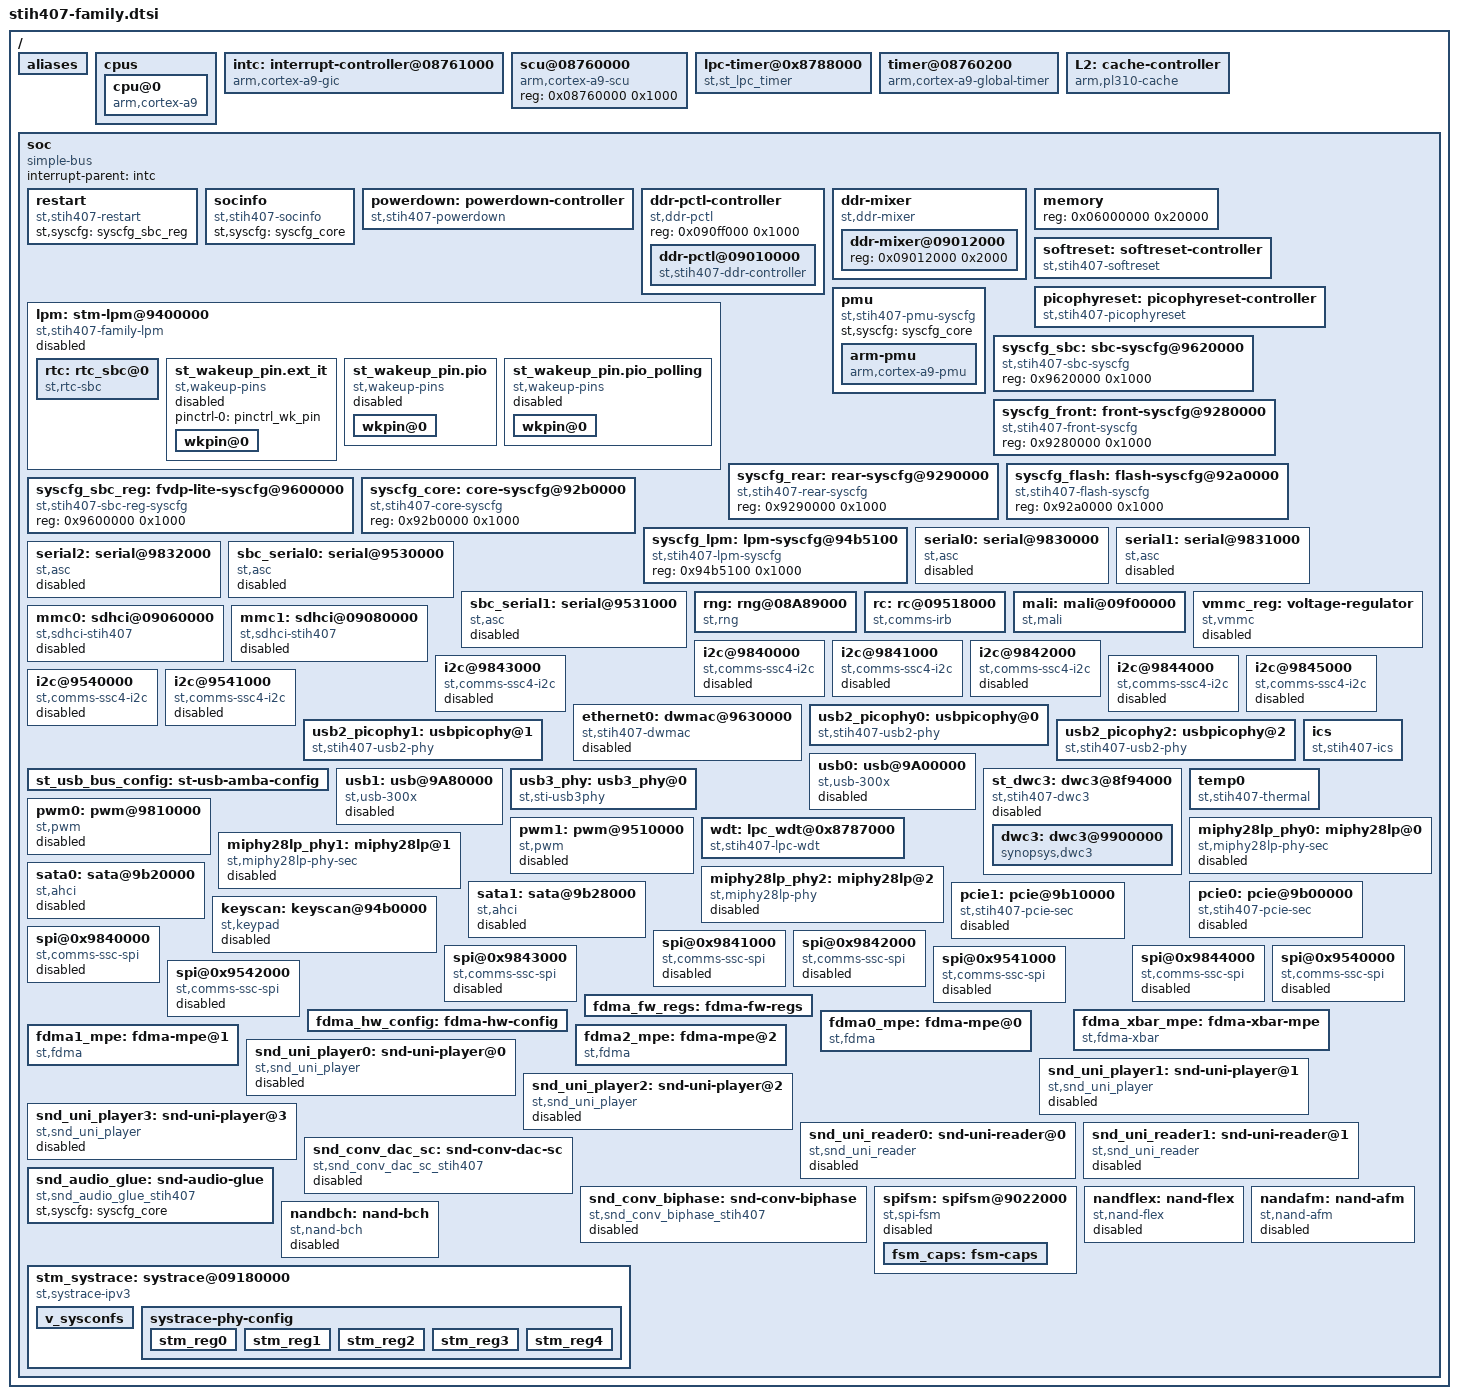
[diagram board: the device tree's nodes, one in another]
/*
 * Copyright (C) 2013 STMicroelectronics Limited.
 * Author: Giuseppe Cavallaro <peppe.cavallaro@st.com>
 *
 * This program is free software; you can redistribute it and/or modify
 * it under the terms of the GNU General Public License version 2 as
 * publishhed by the Free Software Foundation.
 */
#include "stih407-pinctrl.dtsi"
#include <dt-bindings/reset-controller/stih407-resets.h>
#include <dt-bindings/phy/phy-miphy28lp.h>
#include <dt-bindings/gpio/gpio-st-wakeup.h>

#define CLK_PCM_0 0
#define CLK_PCM_1 1
#define CLK_PCM_2 2
#define CLK_SPDIF 3

/ {
	#address-cells = <1>;
	#size-cells = <1>;

	aliases {
		fdma0 = &fdma0_mpe;
		fdma1 = &fdma1_mpe;
		fdma2 = &fdma2_mpe;
		fdmaxbar0 = &fdma_xbar_mpe;
	};

	cpus {
		#address-cells = <1>;
		#size-cells = <0>;
		cpu@0 {
			device_type = "cpu";
			compatible = "arm,cortex-a9";
			reg = <0>;
			clocks = <&CLK_M_A9>;
			clock-names = "cpu";
			operating-points = <
				/* kHz    ignored */
				 1200000  1000000
				  600000  1000000
				  300000  1000000
			>;
			clock-latency = <100000>;
		};
	};

	intc: interrupt-controller@08761000 {
		compatible = "arm,cortex-a9-gic";
		#interrupt-cells = <3>;
		interrupt-controller;
		reg = <0x08761000 0x1000>,
		      <0x08760100 0x100>;
	};

	scu@08760000 {
		compatible = "arm,cortex-a9-scu";
		reg = <0x08760000 0x1000>;
	};

	lpc-timer@0x8788000 {
		compatible = "st,st_lpc_timer";
		reg = <0x8788000 0x1000>;
		clock-names = "lpc_clk";
		clocks = <&CLK_S_D3_FLEXGEN CLK_LPC_1>;
	};

	timer@08760200 {
		interrupt-parent = <&intc>;
		compatible = "arm,cortex-a9-global-timer";
		reg = <0x08760200 0x100>;
		interrupts = <GIC_PPI 11 IRQ_TYPE_LEVEL_HIGH>;
		clocks = <&arm_periph_clk>;
	};

	L2: cache-controller {
		compatible = "arm,pl310-cache";
		reg = <0x08762000 0x1000>;
		arm,data-latency = <3 3 3>;
		arm,tag-latency = <2 2 2>;
		cache-unified;
		cache-level = <2>;
	};

	soc {
		#address-cells = <1>;
		#size-cells = <1>;
		interrupt-parent = <&intc>;
		ranges;
		compatible = "simple-bus";

		restart {
			compatible = "st,stih407-restart";
			st,syscfg = <&syscfg_sbc_reg>;
		};

		socinfo {
			compatible = "st,stih407-socinfo";
			st,syscfg = <&syscfg_core>;
		};

		powerdown: powerdown-controller {
			#reset-cells = <1>;
			compatible = "st,stih407-powerdown";
		};

		ddr-pctl-controller {
			#address-cells = <1>;
			#size-cells = <1>;
			ranges;
			compatible = "st,ddr-pctl", "simple-bus";
			reg = <0x090ff000 0x1000>;
			reg-names = "ddr_pll";
			ddr-pctl@09010000 {
				compatible = "st,stih407-ddr-controller", "st,ddr-controller";
				reg = <0x09010000 0x2000>;
				st,syscfg = <&syscfg_core>;
			};
		};

		ddr-mixer {
			#address-cells = <1>;
			#size-cells = <1>;
			ranges;
			compatible = "st,ddr-mixer", "simple-bus";
			ddr-mixer@09012000 {
				reg = <0x09012000 0x2000>;
			};
		};

		memory {
			device_type = "eram";
			reg = <0x06000000 0x20000>;
			reg-names = "eram_1";
		};

		lpm:stm-lpm@9400000 {
			compatible = "st,stih407-family-lpm", "st,lpm";
			reg = <0x9400000 0xa0000>,
			<0x94b4000 0x400>,
			<0x94b5100 0x100>,
			<0x020000 0x0>;
			reg-names = "base", "mailbox", "confreg", "pmem";
			interrupts = <GIC_SPI 144 IRQ_TYPE_NONE>;
			st,fw_name = "lpm-fw-STiH407.elf";
			status = "disabled";

			rtc: rtc_sbc@0 {
				compatible = "st,rtc-sbc";
			};

			st_wakeup_pin.ext_it {
				compatible = "st,wakeup-pins";
				status = "disabled";
				pinctrl-names = "default";
				pinctrl-0 = <&pinctrl_wk_pin>;
				wkpin@0 {
					interrupts = <GIC_SPI 184 IRQ_TYPE_NONE>;
					label = "ext_it_wakeup";
					st,pio_use = <EXT_IT_WAKEUP_MODE>;
					st,ext_it_num = <2>;
				};
			};

			st_wakeup_pin.pio {
				compatible = "st,wakeup-pins";
				status = "disabled";
				wkpin@0 {
					label = "pio_wakeup";
					gpios = <&PIO3 3>;
					st,pio_use = <PIO_WAKEUP_MODE>;
					st,pio_dir = <GPIO_AS_INPUT>;
					st,int_enabled;
				};
			};

			st_wakeup_pin.pio_polling {
				compatible = "st,wakeup-pins";
				status = "disabled";
				wkpin@0 {
					label = "pio_polling_wakeup";
					gpios = <&PIO3 3>;
					st,pio_use = <PIO_WAKEUP_MODE>;
					st,pio_dir = <GPIO_AS_INPUT>;
					st,pio_level = <GPIO_ACTIVE_LOW>;
				};
			};
		};

		softreset: softreset-controller {
			#reset-cells = <1>;
			compatible = "st,stih407-softreset";
		};

		picophyreset: picophyreset-controller {
			#reset-cells = <1>;
			compatible = "st,stih407-picophyreset";
		};

		pmu {
			compatible = "st,stih407-pmu-syscfg";
			st,syscfg = <&syscfg_core>;

			arm-pmu {
				interrupt-parent = <&intc>;
				compatible = "arm,cortex-a9-pmu";
				interrupts = <GIC_PPI 15 IRQ_TYPE_LEVEL_HIGH>;
			};
		};

		syscfg_sbc:sbc-syscfg@9620000{
			compatible = "st,stih407-sbc-syscfg", "syscon";
			reg = <0x9620000 0x1000>;
		};

		syscfg_front:front-syscfg@9280000{
			compatible = "st,stih407-front-syscfg", "syscon";
			reg = <0x9280000 0x1000>;
		};

		syscfg_rear:rear-syscfg@9290000{
			compatible = "st,stih407-rear-syscfg", "syscon";
			reg = <0x9290000 0x1000>;
		};

		syscfg_flash:flash-syscfg@92a0000{
			compatible = "st,stih407-flash-syscfg", "syscon";
			reg = <0x92a0000 0x1000>;
		};

		syscfg_sbc_reg:fvdp-lite-syscfg@9600000{
			compatible = "st,stih407-sbc-reg-syscfg", "syscon";
			reg = <0x9600000 0x1000>;
		};

		syscfg_core:core-syscfg@92b0000{
			compatible = "st,stih407-core-syscfg", "syscon";
			reg = <0x92b0000 0x1000>;
		};

		syscfg_lpm:lpm-syscfg@94b5100{
			compatible = "st,stih407-lpm-syscfg", "syscon";
			reg = <0x94b5100 0x1000>;
		};

		/* Comms block ASCs */
		serial0: serial@9830000{
			compatible = "st,asc";
			status = "disabled";
			reg = <0x9830000 0x2c>;
			interrupts = <GIC_SPI 122 IRQ_TYPE_NONE>;
			pinctrl-names = "default";
			pinctrl-0 = <&pinctrl_serial0>;
			clocks = <&CLK_S_C0_FLEXGEN CLK_EXT2F_A9>;
		};

		serial1: serial@9831000{
			compatible = "st,asc";
			status = "disabled";
			reg = <0x9831000 0x2c>;
			interrupts = <GIC_SPI 123 IRQ_TYPE_NONE>;
			pinctrl-names = "default";
			pinctrl-0 = <&pinctrl_serial1>;
			clocks = <&CLK_S_C0_FLEXGEN CLK_EXT2F_A9>;
		};

		serial2: serial@9832000{
			compatible = "st,asc";
			status = "disabled";
			reg = <0x9832000 0x2c>;
			interrupts = <GIC_SPI 124 IRQ_TYPE_NONE>;
			pinctrl-names = "default";
			pinctrl-0 = <&pinctrl_serial2>;
			clocks = <&CLK_S_C0_FLEXGEN CLK_EXT2F_A9>;
		};

		/* SBC_ASC0 - UART10 */
		sbc_serial0: serial@9530000 {
			compatible = "st,asc";
			status = "disabled";
			reg = <0x9530000 0x2c>;
			interrupts = <GIC_SPI 138 IRQ_TYPE_NONE>;
			pinctrl-names = "default";
			pinctrl-0 = <&pinctrl_sbc_serial0>;
			clocks = <&CLK_SYSIN>;
		};

		/* SBC_ASC1 - UART11 */
		sbc_serial1: serial@9531000 {
			compatible = "st,asc";
			status = "disabled";
			reg = <0x9531000 0x2c>;
			interrupts = <GIC_SPI 139 IRQ_TYPE_NONE>;
			pinctrl-names = "default";
			pinctrl-0 = <&pinctrl_sbc_serial1>;
			clocks = <&CLK_SYSIN>;
		};

		/* RNG */
		rng: rng@08A89000 {
			compatible = "st,rng";
			reg = <0x08A89000 0x1000>;
			clocks = <&CLK_SYSIN>;
		};

		rc: rc@09518000 {
			compatible = "st,comms-irb";
			reg = <0x09518000 0x234>;
			interrupts = <GIC_SPI 132 IRQ_TYPE_NONE>;
			rx-mode = "infrared";
			pinctrl-names = "default";
			pinctrl-0 = <&pinctrl_ir>;
			clocks = <&CLK_SYSIN>;
			resets = <&softreset STIH407_IRB_SOFTRESET>;
		};

		mali: mali@09f00000 {
			compatible = "st,mali";
			reg = <0x09f01000 0x200>,
			      <0x09f00000 0x100>,
			      <0x09f03000 0x100>,
			      <0x09f08000 0x1100>,
			      <0x09f04000 0x100>,
			      <0x09f0a000 0x1100>,
			      <0x09f05000 0x100>,
			      <0x09f0c000 0x1100>,
			      <0x09f06000 0x100>,
			      <0x09f0e000 0x1100>,
			      <0x09f07000 0x100>;

			reg-names = "Mali_L2",
				    "Mali_GP",
				    "Mali_GP_MMU",
				    "Mali_PP0",
				    "Mali_PP0_MMU",
				    "Mali_PP1",
				    "Mali_PP1_MMU",
				    "Mali_PP2",
				    "Mali_PP2_MMU",
				    "Mali_PP3",
				    "Mali_PP3_MMU";

			interrupts = <GIC_SPI 49 IRQ_TYPE_NONE>,
				     <GIC_SPI 50 IRQ_TYPE_NONE>,
				     <GIC_SPI 41 IRQ_TYPE_NONE>,
				     <GIC_SPI 45 IRQ_TYPE_NONE>,
				     <GIC_SPI 42 IRQ_TYPE_NONE>,
				     <GIC_SPI 46 IRQ_TYPE_NONE>,
				     <GIC_SPI 43 IRQ_TYPE_NONE>,
				     <GIC_SPI 47 IRQ_TYPE_NONE>,
				     <GIC_SPI 44 IRQ_TYPE_NONE>,
				     <GIC_SPI 48 IRQ_TYPE_NONE>;

			interrupt-names = "Mali_GP_IRQ",
					  "Mali_GP_MMU_IRQ",
					  "Mali_PP0_IRQ",
					  "Mali_PP0_MMU_IRQ",
					  "Mali_PP1_IRQ",
					  "Mali_PP1_MMU_IRQ",
					  "Mali_PP2_IRQ",
					  "Mali_PP2_MMU_IRQ",
					  "Mali_PP3_IRQ",
					  "Mali_PP3_MMU_IRQ";

			clock-names = "gpu-clk";
			clocks = <&CLK_S_C0_FLEXGEN CLK_ICN_GPU>;
		};

		/*
		 * The table below summarizes which uses the FlashSS Top
		 * registers. For example the vsense register is exclusively
		 * mapped by the voltage regulator, the subset of registers
		 * to manage the eMMC RX/TX delay are only used inside the
		 * SDHCI ST driver.
		 *
		 *----------------------------------------------------------
		 * Offset	   Register		Driver
		 *----------------------------------------------------------
		 *   0x0	FLASHSS_CONFIG		NAND
		 *   0x4	VSENSE_CONFIG		Voltage Regulator
		 *   0x8	eMMC_TX_CLK_DELAY	SDHCI-ST
		 *		 ...
		 */

		vmmc_reg: voltage-regulator {
			compatible = "st,vmmc";
			regulator-name = "vmmc0";
			/* Control register for the VSENSE Module */
			reg = <0x9061004 0x4>;
			status = "disabled";
		};

		mmc0: sdhci@09060000 {
			compatible = "st,sdhci-stih407", "st,sdhci";
			status = "disabled";
			reg = <0x09060000 0x7ff>, <0x9061008 0x20>;
			reg-names = "mmc", "top-mmc-delay";
			interrupts = <GIC_SPI 92 IRQ_TYPE_NONE>;
			interrupt-names = "mmcirq";
			pinctrl-names = "default";
			pinctrl-0 = <&pinctrl_mmc0>;
			clock-names = "mmc";
			clocks = <&CLK_S_C0_FLEXGEN CLK_MMC_0>;
			st,no-hispd-bit;
			vmmc-supply = <&vmmc_reg>;
		};

		mmc1: sdhci@09080000 {
			compatible = "st,sdhci-stih407", "st,sdhci";
			status = "disabled";
			reg = <0x09080000 0x7ff>;
			reg-names = "mmc";
			interrupts = <GIC_SPI 90 IRQ_TYPE_NONE>;
			interrupt-names = "mmcirq";
			pinctrl-names = "default";
			pinctrl-0 = <&pinctrl_sd1>;
			clock-names = "mmc";
			clocks = <&CLK_S_C0_FLEXGEN CLK_MMC_1>;
			resets = <&softreset STIH407_MMC1_SOFTRESET>;
		};

		i2c@9840000 {
			compatible = "st,comms-ssc4-i2c";
			status = "disabled";
			interrupts = <GIC_SPI 112 IRQ_TYPE_LEVEL_HIGH>;
			reg = <0x9840000 0x110>;
			#address-cells = <1>;
			#size-cells = <0>;
			clocks = <&CLK_S_C0_FLEXGEN CLK_EXT2F_A9>;
			clock-names = "ssc";
			clock-frequency = <400000>;
			pinctrl-names = "default";
			pinctrl-0 = <&pinctrl_i2c0_default>;
		};

		i2c@9841000 {
			compatible = "st,comms-ssc4-i2c";
			status = "disabled";
			reg = <0x9841000 0x110>;
			interrupts = <GIC_SPI 113 IRQ_TYPE_LEVEL_HIGH>;
			#address-cells = <1>;
			#size-cells = <0>;
			clocks = <&CLK_S_C0_FLEXGEN CLK_EXT2F_A9>;
			clock-names = "ssc";
			clock-frequency = <400000>;
			pinctrl-names = "default";
			pinctrl-0 = <&pinctrl_i2c1_default>;
		};

		i2c@9842000 {
			compatible = "st,comms-ssc4-i2c";
			status = "disabled";
			reg = <0x9842000 0x110>;
			interrupts = <GIC_SPI 114 IRQ_TYPE_LEVEL_HIGH>;
			#address-cells = <1>;
			#size-cells = <0>;
			clocks = <&CLK_S_C0_FLEXGEN CLK_EXT2F_A9>;
			clock-names = "ssc";
			clock-frequency = <400000>;
			pinctrl-names = "default";
			pinctrl-0 = <&pinctrl_i2c2_default>;
		};

		i2c@9843000 {
			compatible = "st,comms-ssc4-i2c";
			status = "disabled";
			reg = <0x9843000 0x110>;
			interrupts = <GIC_SPI 115 IRQ_TYPE_LEVEL_HIGH>;
			#address-cells = <1>;
			#size-cells = <0>;
			clocks = <&CLK_S_C0_FLEXGEN CLK_EXT2F_A9>;
			clock-names = "ssc";
			clock-frequency = <400000>;
			pinctrl-names = "default";
			pinctrl-0 = <&pinctrl_i2c3_default>;
		};

		i2c@9844000 {
			compatible = "st,comms-ssc4-i2c";
			status = "disabled";
			reg = <0x9844000 0x110>;
			interrupts = <GIC_SPI 116 IRQ_TYPE_LEVEL_HIGH>;
			#address-cells = <1>;
			#size-cells = <0>;
			clocks = <&CLK_S_C0_FLEXGEN CLK_EXT2F_A9>;
			clock-names = "ssc";
			clock-frequency = <400000>;
			pinctrl-names = "default";
			pinctrl-0 = <&pinctrl_i2c4_default>;
		};

		i2c@9845000 {
			compatible = "st,comms-ssc4-i2c";
			status = "disabled";
			reg = <0x9845000 0x110>;
			interrupts = <GIC_SPI 117 IRQ_TYPE_LEVEL_HIGH>;
			#address-cells = <1>;
			#size-cells = <0>;
			clocks = <&CLK_S_C0_FLEXGEN CLK_EXT2F_A9>;
			clock-names = "ssc";
			clock-frequency = <400000>;
			pinctrl-names = "default";
			pinctrl-0 = <&pinctrl_i2c5_default>;
		};


		/* SSCs on SBC */
		i2c@9540000 {
			compatible = "st,comms-ssc4-i2c";
			status = "disabled";
			reg = <0x9540000 0x110>;
			interrupts = <GIC_SPI 135 IRQ_TYPE_LEVEL_HIGH>;
			#address-cells = <1>;
			#size-cells = <0>;
			clocks = <&CLK_SYSIN>;
			clock-names = "ssc";
			clock-frequency = <400000>;
			pinctrl-names = "default";
			pinctrl-0 = <&pinctrl_i2c10_default>;
		};

		i2c@9541000 {
			compatible = "st,comms-ssc4-i2c";
			status = "disabled";
			reg = <0x9541000 0x110>;
			interrupts = <GIC_SPI 136 IRQ_TYPE_LEVEL_HIGH>;
			#address-cells = <1>;
			#size-cells = <0>;
			clocks = <&CLK_SYSIN>;
			clock-names = "ssc";
			clock-frequency = <400000>;
			pinctrl-names = "default";
			pinctrl-0 = <&pinctrl_i2c11_default>;
		};

		ethernet0: dwmac@9630000 {
			device_type = "network";
			status = "disabled";
			compatible = "st,stih407-dwmac", "snps,dwmac", "snps,dwmac-3.710";
			reg = <0x9630000 0x8000>, <0x80 0x4>;
			reg-names = "stmmaceth", "sti-ethconf";

			st,syscon = <&syscfg_sbc_reg>;
			st,gmac_en;
			resets = <&softreset STIH407_ETH1_SOFTRESET>;
			reset-names = "stmmaceth";

			interrupts = <GIC_SPI 98 IRQ_TYPE_NONE>,
				     <GIC_SPI 99 IRQ_TYPE_NONE>,
				     <GIC_SPI 100 IRQ_TYPE_NONE>;
			interrupt-names = "macirq", "eth_wake_irq", "eth_lpi";

			snps,pbl = <32>;

			pinctrl-names = "default";
			pinctrl-0 = <&pinctrl_rgmii1>;

			clock-names = "stmmaceth", "sti-ethclk";
			clocks = <&CLK_S_C0_FLEXGEN CLK_EXT2F_A9>,
				 <&CLK_S_C0_FLEXGEN CLK_ETH_PHY>;
		};

		/* Generic picoPHY */
		usb2_picophy0: usbpicophy@0 {
			compatible = "st,stih407-usb2-phy";
			reg =	<0xf8 0x04>,	/* syscfg 5062 */
				<0xf4 0x04>;    /* syscfg 5061 */
			reg-names =	"param",
					"ctrl";
			#phy-cells = <0>;

			st,syscfg = <&syscfg_core>;
			resets = <&softreset STIH407_PICOPHY_SOFTRESET>,
				 <&picophyreset STIH407_PICOPHY0_RESET>;
			reset-names = "global",
				      "port";
		};

		usb2_picophy1: usbpicophy@1 {
			compatible = "st,stih407-usb2-phy";
			#phy-cells = <0>;
			reg =	<0xfc 0x04>,	/* syscfg 5063 */
				<0xf4 0x04>;    /* syscfg 5061 */
			reg-names =	"param",
					"ctrl";

			st,syscfg = <&syscfg_core>;
			resets = <&softreset STIH407_PICOPHY_SOFTRESET>,
				 <&picophyreset STIH407_PICOPHY1_RESET>;
			reset-names = "global",
				      "port";
		};

		usb2_picophy2: usbpicophy@2 {
			compatible = "st,stih407-usb2-phy";
			#phy-cells = <0>;
			reg =	<0x100 0x04>,	/* syscfg 5064 */
				<0xf4 0x04>;    /* syscfg 5061 */
			reg-names =	"param",
					"ctrl";

			st,syscfg = <&syscfg_core>;
			resets = <&softreset STIH407_PICOPHY_SOFTRESET>,
				 <&picophyreset STIH407_PICOPHY2_RESET>;
			reset-names = "global",
				      "port";
			st,txvreftune = <0xb>; /* +16% in HS DC level voltage */
		};

		st_usb_bus_config: st-usb-amba-config {
			st,bridge_type2;
			st,sd_config_missing;
			st,complete_on_error;
			st,read_ahead;
			st,max_opcode_LD64_ST64;
			st,chunks_in_msg = <0>;
			st,packets_in_chunk = <2>;
			st,threshold = <256>;
		};

		usb0: usb@9A00000 {
			compatible = "st,usb-300x";
			status = "disabled";
			st,amba-config = <&st_usb_bus_config>;
			reg = <0x9a03c00 0x100>,
			      <0x9a03e00 0x100>,
			      <0x9a03f00 0x100>;
			reg-names = "ohci", "ehci", "protocol";
			interrupts = <GIC_SPI 151 IRQ_TYPE_NONE>,
				     <GIC_SPI 180 IRQ_TYPE_NONE>;
			interrupt-names = "ehci","ohci";
			pinctrl-names = "default";
			pinctrl-0 = <&pinctrl_usb0>;
			clocks = <&CLK_S_C0_FLEXGEN CLK_TX_ICN_DISP_0>;
			clock-names = "ic";
			resets = <&powerdown STIH407_USB2_PORT0_POWERDOWN>,
				 <&softreset STIH407_USB2_PORT0_SOFTRESET>;
			reset-names = "power", "softreset";

			phys = <&usb2_picophy0>;
			phy-names = "usb2-phy";
		};

		usb1: usb@9A80000 {
			compatible = "st,usb-300x";
			status = "disabled";
			st,amba-config = <&st_usb_bus_config>;
			reg = <0x9a83c00 0x100>,
			      <0x9a83e00 0x100>,
			      <0x9a83f00 0x100>;
			reg-names = "ohci", "ehci", "protocol";
			interrupts = <GIC_SPI 153 IRQ_TYPE_NONE>,
				     <GIC_SPI 181 IRQ_TYPE_NONE>;
			interrupt-names = "ehci","ohci";
			pinctrl-names = "default";
			pinctrl-0 = <&pinctrl_usb1>;
			clocks = <&CLK_S_C0_FLEXGEN CLK_TX_ICN_DISP_0>;
			clock-names = "ic";
			resets = <&powerdown STIH407_USB2_PORT1_POWERDOWN>,
				 <&softreset STIH407_USB2_PORT1_SOFTRESET>;
			reset-names = "power", "softreset";

			phys = <&usb2_picophy1>;
			phy-names = "usb2-phy";
		};

		usb3_phy: usb3_phy@0 {
			compatible = "st,sti-usb3phy";
			#phy-cells = <0>;
			resets = <&softreset STIH407_MIPHY2_SOFTRESET>;
			reg = <0x08f90000 0xff>, <0x08f95000 0xff>;
			reg-names = "usb3-uport", "pipew";
			st,syscfg = <&syscfg_core>;
		};

		st_dwc3: dwc3@8f94000 {
			status = "disabled";
			compatible = "st,stih407-dwc3";
			reg = <0x08f94000 0x1000>, <0x110 0x4>;
			reg-names = "reg-glue", "syscfg-reg";
			st,syscfg = <&syscfg_core>;
			resets = <&powerdown STIH407_USB3_POWERDOWN>,
			<&softreset STIH407_MIPHY2_SOFTRESET>;
			reset-names = "power", "soft";
			#address-cells = <1>;
			#size-cells = <1>;
			pinctrl-names = "default";
			pinctrl-0 = <&pinctrl_usb3>;
			ranges;

			dwc3: dwc3@9900000 {
				compatible = "synopsys,dwc3";
				reg = <0x09900000 0x100000>;
				interrupts = <GIC_SPI 155 IRQ_TYPE_NONE>;

				/* usb2 picophy port2, MiPHY2 port for USB3 */
				phys = <&usb2_picophy2>;
				phy-names = "usb2-phy";

				usb3-phy = <&usb3_phy>;
			};
		};

		ics {
			#clock-cells = <1>;
			compatible = "st,stih407-ics";

			clocks = <&CLK_S_C0_FLEXGEN 19>,
					 <&CLK_S_C0_FLEXGEN 20>,
					 <&CLK_S_C0_FLEXGEN 21>;

			clock-names = "clk_00", /* CLK_ST231_AUD_0 */
						  "clk_01", /* CLK_ST231_GP_1 */
						  "clk_02"; /* CLK_ST231_DMU */
		};

		temp0{
			compatible = "st,stih407-thermal";
			reg = <0x91a0000 0x28>;
			clock-names = "thermal";
			clocks = <&CLK_SYSIN>;
			interrupts = <GIC_SPI 205 IRQ_TYPE_EDGE_RISING>;
		};

		/* COMMS PWM MODULE */
		pwm0: pwm@9810000 {
			compatible = "st,pwm";
			status = "disabled";
			#pwm-cells = <2>;
			reg = <0x9810000 0x68>;
			pinctrl-names = "default";
			pinctrl-0 = <&pinctrl_pwm0_chan0_default>;
			clock-names = "pwm";
			clocks = <&CLK_SYSIN>;
			st,pwm-num-chan = <1>;
		};

		/* SBC PWM MODULE */
		pwm1: pwm@9510000 {
			compatible = "st,pwm";
			status = "disabled";
			#pwm-cells = <2>;
			reg = <0x9510000 0x68>;
			pinctrl-names = "default";
			pinctrl-0 = <&pinctrl_pwm1_chan0_default
				     &pinctrl_pwm1_chan1_default
				     &pinctrl_pwm1_chan2_default
				     &pinctrl_pwm1_chan3_default>;

			clock-names = "pwm";
			clocks = <&CLK_SYSIN>;
			st,pwm-num-chan = <4>;
		};

		wdt: lpc_wdt@0x8787000 {
			compatible = "st,stih407-lpc-wdt";
			reg = <0x8787000 0x1000>;
			clock-names = "lpc_wdt";
			clocks = <&CLK_S_D3_FLEXGEN CLK_LPC_0>;
			timeout-sec = <600>;
			st,syscfg = <&syscfg_core>;
		};

		miphy28lp_phy0: miphy28lp@0 {
			compatible = "st,miphy28lp-phy-sec";
			#phy-cells = <1>;
			reg = <0x9b22000 0xff>,
			      <0x9b09000 0xff>,
			      <0x9b04000 0xff>,
			      <0x114 0x4>,	/* sysctrl MiPHY cntrl */
			      <0x818 0x4>,	/* sysctrl MiPHY status*/
			      <0xe0  0x4>,	/* sysctrl PCIe */
			      <0xec  0x4>;	/* sysctrl SATA */
			reg-names = "sata-up",
				    "pcie-up",
				    "pipew",
				    "miphy-ctrl-glue",
				    "miphy-status-glue",
				    "pcie-glue",
				    "sata-glue";

			st,syscfg = <&syscfg_core>;

			resets = <&softreset STIH407_MIPHY0_SOFTRESET>;
			reset-names = "miphy-sw-rst";

			st,osc-rdy;
			status = "disabled";
		};

		miphy28lp_phy1: miphy28lp@1 {
			compatible = "st,miphy28lp-phy-sec";
			#phy-cells = <1>;
			reg = <0x9b2a000 0xff>,
			      <0x9b19000 0xff>,
			      <0x9b14000 0xff>,
			      <0x118 0x4>,
			      <0x81c 0x4>,
			      <0xe4  0x4>,
			      <0xf0  0x4>;

			reg-names = "sata-up",
				    "pcie-up",
				    "pipew",
				    "miphy-ctrl-glue",
				    "miphy-status-glue",
				    "pcie-glue",
				    "sata-glue";

			st,syscfg = <&syscfg_core>;

			resets = <&softreset STIH407_MIPHY1_SOFTRESET>;
			reset-names = "miphy-sw-rst";
			status = "disabled";
		};

		miphy28lp_phy2: miphy28lp@2 {
			compatible = "st,miphy28lp-phy";
			#phy-cells = <1>;
			reg = <0x8f95000 0xff>,
			      <0x8f90000 0xff>,
			      <0x11c 0x4>,
			      <0x820 0x4>;

			reg-names = "pipew",
				    "usb3-up",
				    "miphy-ctrl-glue",
				    "miphy-status-glue";

			st,syscfg = <&syscfg_core>;

			resets = <&softreset STIH407_MIPHY2_SOFTRESET>;
			reset-names = "miphy-sw-rst";
			status = "disabled";
		};

		sata0: sata@9b20000 {
			compatible = "st,ahci";
			reg = <0x9b20000 0x1000>;

			interrupts = <GIC_SPI 159 IRQ_TYPE_NONE>;
			interrupt-names = "hostc";

			status = "disabled";

			phys = <&miphy28lp_phy0 MIPHY28LP_SATA>;
			phy-names = "ahci_phy";

			resets = <&powerdown STIH407_SATA0_POWERDOWN>,
				 <&softreset STIH407_SATA0_SOFTRESET>,
				 <&softreset STIH407_SATA0_PWR_SOFTRESET>;
			reset-names = "pwr-dwn",
				      "sw-rst",
				      "pwr-rst";

			clock-names = "ahci_clk";
			clocks = <&CLK_S_C0_FLEXGEN CLK_ICN_REG>;
		};

		sata1: sata@9b28000 {
			compatible = "st,ahci";
			reg = <0x9b28000 0x1000>;

			interrupts = <GIC_SPI 170 IRQ_TYPE_NONE>;
			interrupt-names = "hostc";

			status = "disabled";

			phys = <&miphy28lp_phy1 MIPHY28LP_SATA>;
			phy-names = "ahci_phy";

			resets = <&powerdown STIH407_SATA1_POWERDOWN>,
				 <&softreset STIH407_SATA1_SOFTRESET>,
				 <&softreset STIH407_SATA1_PWR_SOFTRESET>;
			reset-names = "pwr-dwn",
				      "sw-rst",
				      "pwr-rst";

			clock-names = "ahci_clk";
			clocks = <&CLK_S_C0_FLEXGEN CLK_ICN_REG>;
		};

		pcie0: pcie@9b00000 {
			compatible = "st,stih407-pcie-sec";
			device_type = "pci";
			reg = <0x09b00000 0x00001000   /* cntrl registers */
			       0x2fff0000 0x00010000   /* configuration space */
			       0x40000000 0x80000000   /* lmi mem window */
			       0xd8 0x04               /* syscfg 5054 */
			       0xe0 0x04>;             /* syscfg 5056 */

			reg-names = "pcie cntrl",
				    "pcie cs",
				    "mem-window",
				    "syscfg0",
				    "syscfg1";

			interrupts = <GIC_SPI 160 IRQ_TYPE_LEVEL_HIGH>,
				     <GIC_SPI 161 IRQ_TYPE_LEVEL_HIGH>,
				     <GIC_SPI 162 IRQ_TYPE_LEVEL_HIGH>,
				     <GIC_SPI 163 IRQ_TYPE_LEVEL_HIGH>,
				     <GIC_SPI 166 IRQ_TYPE_LEVEL_HIGH>,
				     <GIC_SPI 164 IRQ_TYPE_LEVEL_HIGH>;
			interrupt-names = "pcie inta",
				          "pcie intb",
					  "pcie intc",
					  "pcie intd",
					  "pcie syserr",
					  "msi";

			bus-range = <0x00 0x7f>;
			#address-cells = <3>;
			#size-cells = <2>;
			ranges = <0x81000000 0 0x00001000 0x00001000 0 0x00007000   /* dummy I/O space */
				  0x82000000 0 0x20000000 0x20000000 0 0x05550000   /* non-prefetchable memory */
				  0xc2000000 0 0x25550000 0x25550000 0 0x0AAA0000>; /* prefetchable memory */
			st,syscfg = <&syscfg_core>;

			resets = <&powerdown STIH407_PCIE0_POWERDOWN>,
				 <&softreset STIH407_PCIE0_SOFTRESET>;

			reset-names = "power",
				      "softreset";

			phys = <&miphy28lp_phy0 MIPHY28LP_PCIE>;
			phy-names = "pcie_phy";

			status = "disabled";
		};

		pcie1: pcie@9b10000 {
			compatible = "st,stih407-pcie-sec";
			device_type = "pci";
			reg = <0x09b10000 0x00001000   /* cntrl registers */
			       0x3fff0000 0x00010000   /* configuration space */
			       0x40000000 0x80000000   /* lmi mem window */
			       0xdc 0x04               /* syscfg 5055 */
			       0xe4 0x04>;             /* syscfg 5057 */
			reg-names = "pcie cntrl",
				    "pcie cs",
				    "mem-window",
				    "syscfg0",
				    "syscfg1";

			interrupts = <GIC_SPI 171 IRQ_TYPE_LEVEL_HIGH>,
				     <GIC_SPI 172 IRQ_TYPE_LEVEL_HIGH>,
				     <GIC_SPI 173 IRQ_TYPE_LEVEL_HIGH>,
				     <GIC_SPI 174 IRQ_TYPE_LEVEL_HIGH>,
				     <GIC_SPI 177 IRQ_TYPE_LEVEL_HIGH>,
				     <GIC_SPI 175 IRQ_TYPE_LEVEL_HIGH>;
			interrupt-names = "pcie inta",
					  "pcie intb",
					  "pcie intc",
					  "pcie intd",
					  "pcie syserr",
					  "msi";

			bus-range = <0x80 0xff>;
			#address-cells = <3>;
			#size-cells = <2>;
			ranges = <0x81000000 0 0x00008000 0x00008000 0 0x00008000   /* dummy I/O space */
				  0x82000000 0 0x30000000 0x30000000 0 0x05550000   /* non-prefetchable memory */
				  0xc2000000 0 0x35550000 0x35550000 0 0x0AAA0000>; /* prefetchable memory */
			st,syscfg = <&syscfg_core>;

			resets = <&powerdown STIH407_PCIE1_POWERDOWN>,
				 <&softreset STIH407_PCIE1_SOFTRESET>;
			reset-names = "power", "softreset";

			phys = <&miphy28lp_phy1 MIPHY28LP_PCIE>;
			phy-names = "pcie_phy";

			status = "disabled";
		};

		keyscan: keyscan@94b0000 {
			compatible = "st,keypad";
			status = "disabled";
			reg = <0x94b0000 0x2000>;
			interrupts = <GIC_SPI 141 IRQ_TYPE_NONE>;
			clocks = <&CLK_SYSIN>;
			pinctrl-names = "default";
			resets = <&softreset STIH407_KEYSCAN_SOFTRESET>;
		};

		spi@0x9840000 {
			compatible = "st,comms-ssc-spi";
			status = "disabled";
			reg = <0x9840000 0x110>;
			interrupts = <GIC_SPI 112 IRQ_TYPE_LEVEL_HIGH>;
			clocks = <&CLK_S_C0_FLEXGEN CLK_EXT2F_A9>;
			clock-names = "ssc";
			pinctrl-names = "default";
			pinctrl-0 = <&pinctrl_spi0_default>;
		};

		spi@0x9841000 {
			compatible = "st,comms-ssc-spi";
			status = "disabled";
			reg = <0x9841000 0x110>;
			interrupts = <GIC_SPI 113 IRQ_TYPE_LEVEL_HIGH>;
			clocks = <&CLK_S_C0_FLEXGEN CLK_EXT2F_A9>;
			clock-names = "ssc";
			pinctrl-names = "default";
			pinctrl-0 = <&pinctrl_spi1_default>;
		};

		spi@0x9842000 {
			compatible = "st,comms-ssc-spi";
			status = "disabled";
			reg = <0x9842000 0x110>;
			interrupts = <GIC_SPI 114 IRQ_TYPE_LEVEL_HIGH>;
			clocks = <&CLK_S_C0_FLEXGEN CLK_EXT2F_A9>;
			clock-names = "ssc";
			pinctrl-names = "default";
			pinctrl-0 = <&pinctrl_spi2_default>;
		};

		spi@0x9843000 {
			compatible = "st,comms-ssc-spi";
			status = "disabled";
			reg = <0x9843000 0x110>;
			interrupts = <GIC_SPI 115 IRQ_TYPE_LEVEL_HIGH>;
			clocks = <&CLK_S_C0_FLEXGEN CLK_EXT2F_A9>;
			clock-names = "ssc";
			pinctrl-names = "default";
			pinctrl-0 = <&pinctrl_spi3_default>;
		};

		spi@0x9844000 {
			compatible = "st,comms-ssc-spi";
			status = "disabled";
			reg = <0x9844000 0x110>;
			interrupts = <GIC_SPI 116 IRQ_TYPE_LEVEL_HIGH>;
			clocks = <&CLK_S_C0_FLEXGEN CLK_EXT2F_A9>;
			clock-names = "ssc";
			pinctrl-names = "default";
			pinctrl-0 = <&pinctrl_spi4_default>;
		};

		spi@0x9540000 {
			compatible = "st,comms-ssc-spi";
			status = "disabled";
			reg = <0x9540000 0x110>;
			interrupts = <GIC_SPI 135 IRQ_TYPE_LEVEL_HIGH>;
			clocks = <&CLK_SYSIN>;
			clock-names = "ssc";
			pinctrl-names = "default";
			pinctrl-0 = <&pinctrl_spi10_default>;
		};

		spi@0x9541000 {
			compatible = "st,comms-ssc-spi";
			status = "disabled";
			reg = <0x9541000 0x110>;
			interrupts = <GIC_SPI 136 IRQ_TYPE_LEVEL_HIGH>;
			clocks = <&CLK_SYSIN>;
			clock-names = "ssc";
			pinctrl-names = "default";
			pinctrl-0 = <&pinctrl_spi11_default>;
		};

		spi@0x9542000 {
			compatible = "st,comms-ssc-spi";
			status = "disabled";
			reg = <0x9542000 0x110>;
			interrupts = <GIC_SPI 137 IRQ_TYPE_LEVEL_HIGH>;
			clocks = <&CLK_SYSIN>;
			clock-names = "ssc";
			pinctrl-names = "default";
			pinctrl-0 = <&pinctrl_spi12_default>;
		};

		/* SSC2 */
		spi@0x9842000 {
			compatible = "st,comms-ssc-spi";
			reg = <0x9842000 0x110>;
			interrupts = <GIC_SPI 114 IRQ_TYPE_LEVEL_HIGH>;
			clocks = <&CLK_S_C0_FLEXGEN CLK_EXT2F_A9>;
			clock-names = "ssc";
			pinctrl-names = "default";
			pinctrl-0 = <&pinctrl_spi0_default>;
			cs-gpios = <&PIO12 4 0>;
			status = "disabled";
		};

		/* FDMA */
		fdma_fw_regs: fdma-fw-regs {
			fw-rev-id = <0x10000>;
			fw-mchi-rx-nb-cur = <0x100c4>;
			fw-mchi-rx-nb-all = <0x100c8>;
			fw-cmd-statn = <0x10200>;
			fw-req-ctln = <0x10240>;
			fw-ptrn = <0x10800>;
			fw-ctrln = <0x10804>;
			fw-cntn = <0x10808>;
			fw-saddrn = <0x1080c>;
			fw-daddrn = <0x10810>;
			fw-node-size = <128>;
		};

		fdma_hw_config: fdma-hw-config {
			slim-reg-id = <0x0>;
			slim-reg-ver = <0x4>;
			slim-reg-en = <0x8>;
			slim-reg-clk-gate = <0xc>;
			slim-reg-slim-pc = <0x20>;

			dmem-offset = <0x10000>;
			dmem-size = <0x3000>;

			periph-reg-sync-reg = <0x17f88>;
			periph-reg-cmd-sta = <0x17fc0>;
			periph-reg-cmd-set = <0x17fc4>;
			periph-reg-cmd-clr = <0x17fc8>;
			periph-reg-cmd-mask = <0x17fcc>;
			periph-reg-int-sta = <0x17fd0>;
			periph-reg-int-set = <0x17fd4>;
			periph-reg-int-clr = <0x17fd8>;
			periph-reg-int-mask = <0x17fdc>;

			imem-offset = <0x18000>;
			imem-size = <0x8000>;
		};

		fdma_xbar_mpe: fdma-xbar-mpe {
			compatible = "st,fdma-xbar";
			reg = <0x8e80000 0x1000>;
			first-fdma = <1>;
			last-fdma = <1>;
		};

		fdma0_mpe: fdma-mpe@0 {
			compatible = "st,fdma";
			reg = <0x8e20000 0x20000>;
			interrupts = <GIC_SPI 5 IRQ_TYPE_NONE>;
			hw-conf = <&fdma_hw_config>;
			fw-regs = <&fdma_fw_regs>;
			xbar = <0>;
			fw-name = "fdma_STiH407_0.elf";
			clocks = <&CLK_S_C0_FLEXGEN CLK_FDMA>,
				 <&CLK_S_C0_FLEXGEN CLK_EXT2F_A9>,
				 <&CLK_S_C0_FLEXGEN CLK_EXT2F_A9>,
				 <&CLK_S_C0_FLEXGEN CLK_EXT2F_A9>;
			clock-names = "fdma_slim",
				      "fdma_hi",
				      "fdma_low",
				      "fdma_ic";
		};

		fdma1_mpe: fdma-mpe@1 {
			compatible = "st,fdma";
			reg = <0x8e40000 0x20000>;
			interrupts = <GIC_SPI 7 IRQ_TYPE_NONE>;
			hw-conf = <&fdma_hw_config>;
			fw-regs = <&fdma_fw_regs>;
			xbar = <0>;
			fw-name = "fdma_STiH407_1.elf";
			clocks = <&CLK_S_C0_FLEXGEN CLK_FDMA>,
				 <&CLK_S_C0_FLEXGEN CLK_TX_ICN_DMU>,
				 <&CLK_S_C0_FLEXGEN CLK_TX_ICN_DMU>,
				 <&CLK_S_C0_FLEXGEN CLK_EXT2F_A9>;
			clock-names = "fdma_slim",
				      "fdma_hi",
				      "fdma_low",
				      "fdma_ic";
		};

		fdma2_mpe: fdma-mpe@2 {
			compatible = "st,fdma";
			reg = <0x8e60000 0x20000>;
			interrupts = <GIC_SPI 9 IRQ_TYPE_NONE>;
			hw-conf = <&fdma_hw_config>;
			fw-regs = <&fdma_fw_regs>;
			xbar = <0>;
			fw-name = "fdma_STiH407_2.elf";
			clocks = <&CLK_S_C0_FLEXGEN CLK_FDMA>,
				 <&CLK_S_C0_FLEXGEN CLK_EXT2F_A9>,
				 <&CLK_S_C0_FLEXGEN CLK_TX_ICN_DISP_0>,
				 <&CLK_S_C0_FLEXGEN CLK_EXT2F_A9>;
			clock-names = "fdma_slim",
			              "fdma_hi",
				      "fdma_low",
				      "fdma_ic";
		};

		/* Uniperipheral */
		snd_uni_player0: snd-uni-player@0 {
			compatible = "st,snd_uni_player";
			status = "disabled";
			reg = <0x8D80000 0x158>;
			interrupts = <GIC_SPI 84 IRQ_TYPE_NONE>;
			version = <5>;
			dmas = <&fdma0_mpe>;
			dma-names = "stm-fdma.3";
			fdma-initiator = <0>;
			fdma-request-line = <2>;
			fdma-direct-conn = <1>;
			description = "Uni Player #0 (HDMI)";
			card-device = <0>;
			mode = "HDMI";
			iec958-lr-pol = <0>;
			iec958-i2s-mode = <0>;
			channels = <8>;
			standby = <1>;
			underflow = <1>;
			clocks = <&CLK_S_D0_FLEXGEN CLK_PCM_0>;
			clock-names = "uni_player_clk";
		};

		snd_uni_player1: snd-uni-player@1 {
			compatible = "st,snd_uni_player";
			status = "disabled";
			reg = <0x8D81000  0x158>;
			interrupts = <GIC_SPI 85 IRQ_TYPE_NONE>;
			version = <5>;
			dmas = <&fdma0_mpe>;
			dma-names = "stm-fdma.0";
			fdma-initiator = <0>;
			fdma-request-line = <3>;
			fdma-direct-conn = <1>;
			description = "Uni Player #1 (PIO)";
			card-device = <1>;
			mode = "PCM";
			channels = <8>;
			standby = <1>;
			underflow = <1>;
			pinctrl-names = "default";
			pinctrl-0 = <&pinctrl_i2s_8ch_out>;
			clocks = <&CLK_S_D0_FLEXGEN CLK_PCM_1>;
			clock-names = "uni_player_clk";
			auto-suspend-delay = <5000>;
		};

		snd_uni_player2: snd-uni-player@2 {
			compatible = "st,snd_uni_player";
			status = "disabled";
			reg = <0x8D82000  0x158>;
			interrupts = <GIC_SPI 86 IRQ_TYPE_NONE>;
			version = <5>;
			dmas = <&fdma0_mpe>;
			dma-names = "stm-fdma.0";
			fdma-initiator = <0>;
			fdma-request-line = <4>;
			fdma-direct-conn = <1>;
			description = "Uni Player #2 (DAC)";
			card-device = <2>;
			mode = "PCM";
			channels = <2>;
			standby = <1>;
			underflow = <1>;
			s16-swap-lr = <1>;
			clocks = <&CLK_S_D0_FLEXGEN CLK_PCM_2>;
			clock-names = "uni_player_clk";
			auto-suspend-delay = <5000>;
		};

		snd_uni_player3: snd-uni-player@3 {
			compatible = "st,snd_uni_player";
			status = "disabled";
			reg = <0x8D85000  0x158>;
			interrupts = <GIC_SPI 89 IRQ_TYPE_NONE>;
			version = <5>;
			dmas = <&fdma0_mpe>;
			dma-names = "stm-fdma.0";
			fdma-initiator = <0>;
			fdma-request-line = <7>;
			fdma-direct-conn = <1>;
			description = "Uni Player #3 (SPDIF)";
			iec958-lr-pol = <0>;
			iec958-i2s-mode = <1>;
			card-device = <3>;
			mode = "SPDIF";
			channels = <2>;
			standby = <1>;
			underflow = <1>;
			pinctrl-names = "default";
			pinctrl-0 = <&pinctrl_spdif_out>;
			clocks = <&CLK_S_D0_FLEXGEN CLK_SPDIF>;
			clock-names = "uni_player_clk";
			auto-suspend-delay = <5000>;
		};

		snd_uni_reader0: snd-uni-reader@0 {
			compatible = "st,snd_uni_reader";
			status = "disabled";
			reg = <0x8D83000  0x158>;
			interrupts = <GIC_SPI 87 IRQ_TYPE_NONE>;
			version = <3>;
			dmas = <&fdma0_mpe>;
			dma-names = "stm-fdma.0";
			fdma-initiator = <0>;
			fdma-request-line = <5>;
			fdma-direct-conn = <1>;
			description = "Uni Reader #0 (SPDIF)";
			card-device = <4>;
			channels = <8>;
			pinctrl-names = "default";
			pinctrl-0 = <&pinctrl_i2s_8ch_in>;
		};

		snd_uni_reader1: snd-uni-reader@1 {
			compatible = "st,snd_uni_reader";
			status = "disabled";
			reg = <0x8D84000  0x158>;
			interrupts = <GIC_SPI 88 IRQ_TYPE_NONE>;
			version = <3>;
			dmas = <&fdma0_mpe>;
			dma-names = "stm-fdma.0";
			fdma-initiator = <0>;
			fdma-request-line = <6>;
			fdma-direct-conn = <1>;
			description = "Uni Reader #1 (HDMI)";
			card-device = <5>;
			channels = <8>;
		};

		snd_conv_dac_sc: snd-conv-dac-sc {
			compatible = "st,snd_conv_dac_sc_stih407";
			status = "disabled";
			source-bus-id = <&snd_uni_player2>;
			channel-to = <1>;
			channel-from = <0>;
			oversampling = <256>;
			st,syscfg = <&syscfg_core>;
		};

		snd_conv_biphase: snd-conv-biphase {
			compatible = "st,snd_conv_biphase_stih407";
			status = "disabled";
			source-bus-id = <&snd_uni_player3>;
			channel-to = <1>;
			channel-from = <0>;
			idle-value = <0>;
			st,syscfg = <&syscfg_core>;
		};

		snd_audio_glue: snd-audio-glue {
			compatible = "st,snd_audio_glue_stih407";
			status = "okay";
			st,syscfg = <&syscfg_core>;
		};

		/* FSM */
		spifsm:	spifsm@9022000{
			compatible = "st,spi-fsm";
			status = "disabled";
			reg = <0x9022000 0x1000>;
			reg-names = "spi-fsm";
			clocks = <&CLK_S_C0_FLEXGEN CLK_FLASH_PROMIP>;
			clock-names = "emi_clk";
			pinctrl-0 = <&pinctrl_fsm>;
			st,syscfg = <&syscfg_core>;
			st,boot-device-reg = <0x8c4>;
			st,boot-device-spi = <0x68>;
			st,boot-device-msk = <0x7c>;
			caps-handle = <&fsm_caps>;

			fsm_caps: fsm-caps {
				no-read-repeat;
				no-write-repeat;
				read-status-clkdiv4;
				dual-mode;		/* DUAL mode */
				quad-mode;		/* QUAD mode */
			};
		};

		nandflex: nand-flex {
			compatible = "st,nand-flex";
			reg = <0x09021000 0x1000>;
			reg-names = "nand_mem";
			clocks = <&CLK_S_C0_FLEXGEN CLK_FLASH_PROMIP>;
			clock-names = "emi_clk";
			pinctrl-names = "default";
			pinctrl-0 = <&pinctrl_nand>;
			st,flex-select-reg = <0x09061000>;
			st,flex-select-msk = <0x1>;
			status = "disabled";
		};

		nandafm: nand-afm {
			compatible = "st,nand-afm";
			reg = <0x09021000 0x1000>, <0x09060800 0x0800>;
			reg-names = "nand_mem", "nand_dma";
			clocks = <&CLK_S_C0_FLEXGEN CLK_FLASH_PROMIP>;
			clock-names = "emi_clk";
			pinctrl-names = "default";
			pinctrl-0 = <&pinctrl_nand>;
			interrupts = <GIC_SPI 94 IRQ_TYPE_NONE>;
			interrupt-names = "nand_irq";
			st,flex-select-reg = <0x09061000>;
			st,flex-select-msk = <0x1>;
			status = "disabled";
		};

		nandbch: nand-bch {
			compatible = "st,nand-bch";
			reg = <0x09021000 0x1000>, <0x09060800 0x0800>;
			reg-names = "nand_mem", "nand_dma";
			clocks = <&CLK_S_C0_FLEXGEN CLK_FLASH_PROMIP>,
				 <&CLK_S_C0_FLEXGEN CLK_NAND>;
			clock-names = "emi_clk", "bch_clk";
			pinctrl-names = "default";
			pinctrl-0 = <&pinctrl_nand>;
			interrupts = <GIC_SPI 94 IRQ_TYPE_NONE>;
			interrupt-names = "nand_irq";
			st,bch-ecc-mode = "auto";
			st,bch-select-reg = <0x09061000>;
			st,bch-select-msk = <0x1>;
			status = "disabled";
		};

		stm_systrace: systrace@09180000 {
			compatible = "st,systrace-ipv3";
			st,syscfg = <&syscfg_core>;
			reg = <0x09180000 0x10000
			       0x09190000 0x1000
			       0x2F8 0x04		/* syscfg 5190 */
			       0x2FC 0x04		/* syscfg 5191 */
			       0x300 0x04		/* syscfg 5192 */
			       0x304 0x04		/* syscfg 5193 */
			       0x308 0x04		/* syscfg 5194 */
			       0x30C 0x04		/* syscfg 5195 */
			       0x310 0x04>;		/* syscfg 5196 */
			reg-names = "stm-systrace-channels",
			            "stm-systrace-conf",
				    "syscfg0",
				    "syscfg1",
				    "syscfg2",
				    "syscfg3",
				    "syscfg4",
				    "syscfg5",
				    "syscfg6";
			pinctrl-names = "default";
			pinctrl-0 = <&pinctrl_systrace_default>;

			v_sysconfs {
				sysconf0 = <0x003f0000>;
				sysconf1 = <0x00580058>;
				sysconf2 = <0x00990098>;
				sysconf3 = <0x00530050>;
				sysconf4 = <0x00550054>;
				sysconf5 = <0x00570056>;
				sysconf6 = <0x03ff03ff>; /* Not the reset value */
			};

			/* STM IP v3 configuration */
			systrace-phy-config {
				stm_reg0 { /* fck = 25Mhz */
				    nam = "STM_CR";  ofs = <0x0000>; val = <0x0600>;
				};
				stm_reg1 {
				    nam = "STM_MCR"; ofs = <0x0008>; val = <0x0000>;
				};
				stm_reg2 { /* Enable all initiators */
				    nam = "STM_TER"; ofs = <0x0010>; val = <0x03ff>;
				};
				stm_reg3 { /*ASYNC period */
				    nam = "STM_FTR"; ofs = <0x0080>; val = <1>;
				};
				stm_reg4 { /*ASYNC period */
				    nam = "STM_CTR"; ofs = <0x0088>; val = <1>;
				};
			};
		};
	};
};
